# ECC_AGGR0_ECC_AGGR register map
Vendor: Texas Instruments
Registers are 32-bit, access not given, reset 0x0 unless marked. A register's access mark holds for its fields unless they carry their own. Offsets are as the file gives them; [hi:lo] are bit positions.

## ECC_AGGR0_ECC_AGGR (part 2 of 4)
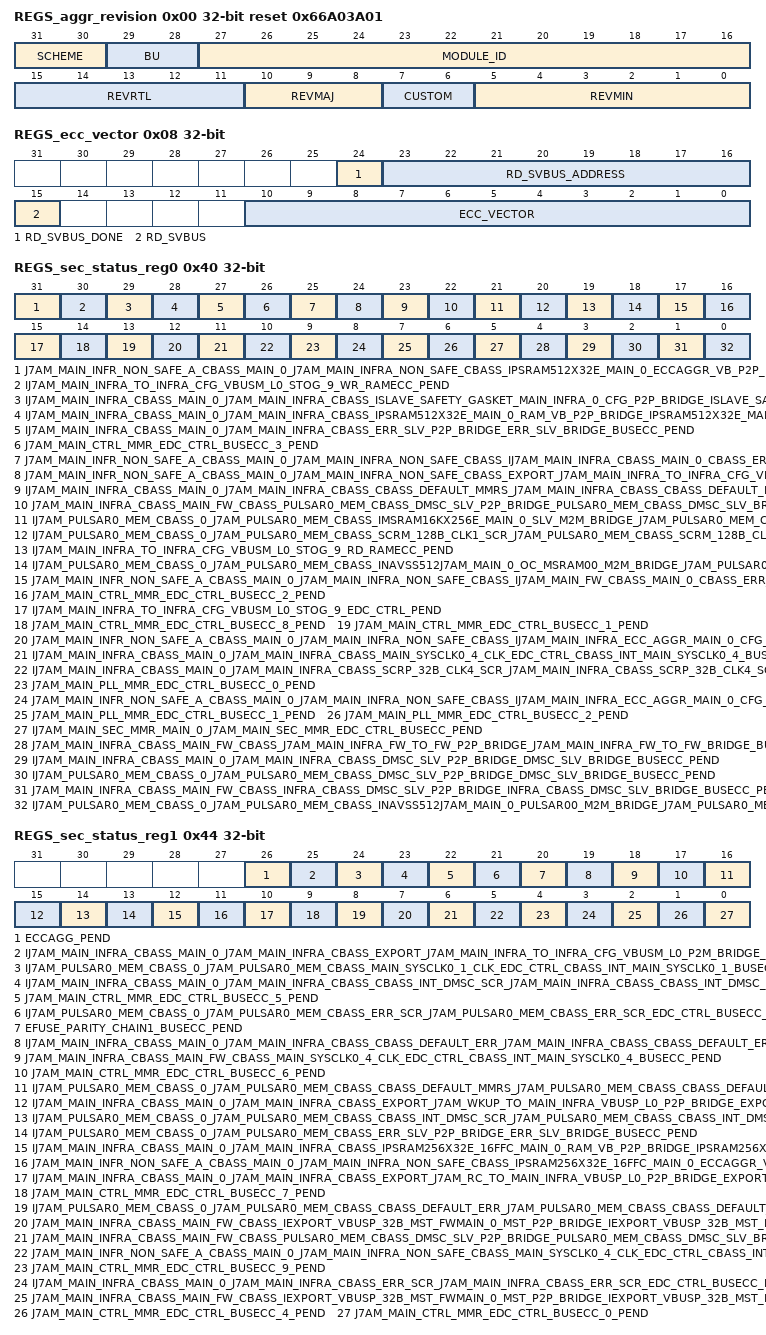
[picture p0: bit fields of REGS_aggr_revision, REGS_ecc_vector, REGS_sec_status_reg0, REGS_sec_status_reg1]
0x00 REGS_aggr_revision ro reset 0x66A03A01 — Revision parameters
  [31:30] SCHEME
  [29:28] BU
  [27:16] MODULE_ID
  [15:11] REVRTL — RTL version
  [10:8] REVMAJ — Major version
  [7:6] CUSTOM — Custom version
  [5:0] REVMIN — Minor version
0x08 REGS_ecc_vector — ECC Vector Register
  [24] RD_SVBUS_DONE — Status to indicate if read on serial VBUS is complete, write of any value will clear this bit. (access R/W1TC)
  [23:16] RD_SVBUS_ADDRESS rw — Read address
  [15] RD_SVBUS — Write 1 to trigger a read on the serial VBUS (access R/W1TS)
  [10:0] ECC_VECTOR rw — Value written to select the corresponding ECC RAM for control or status
0x0C REGS_misc_status ro reset 0x3B — Misc Status
  [10:0] NUM_RAMS — Indicates the number of RAMS serviced by the ECC aggregator
0x10 REGS_reserved_svbus rw — Reference other documents that contain the ECC RAM wrapper and EDC controller serial vbus register sets.
  [31:0] DATA — Serial VBUS register data
0x3C REGS_sec_eoi_reg — EOI Register
  [0] EOI_WR — EOI Register (access R/W1TS)
0x40 REGS_sec_status_reg0 — Interrupt Status Register 0
  [31] J7AM_MAIN_INFR_NON_SAFE_A_CBASS_MAIN_0_J7AM_MAIN_INFRA_NON_SAFE_CBASS_IPSRAM512X32E_MAIN_0_ECCAGGR_VB_P2P_BRIDGE_IPSRAM512X32E_MAIN_0_ECCAGGR_VB_BRIDGE_BUSECC_PEND — Interrupt Pending Status for j7am_main_infr_non_safe_a_cbass_main_0_j7am_main_infra_non_safe_cbass_Ipsram512x32e_main_0_eccaggr_vb_p2p_bridge_Ipsram512x32e_main_0_eccaggr_vb_bridge_busecc_pend (access R/W1TS)
  [30] IJ7AM_MAIN_INFRA_TO_INFRA_CFG_VBUSM_L0_STOG_9_WR_RAMECC_PEND — Interrupt Pending Status for Ij7am_main_infra_to_infra_cfg_vbusm_l0_stog_9_wr_ramecc_pend (access R/W1TS)
  [29] IJ7AM_MAIN_INFRA_CBASS_MAIN_0_J7AM_MAIN_INFRA_CBASS_ISLAVE_SAFETY_GASKET_MAIN_INFRA_0_CFG_P2P_BRIDGE_ISLAVE_SAFETY_GASKET_MAIN_INFRA_0_CFG_BRIDGE_BUSECC_PEND — Interrupt Pending Status for Ij7am_main_infra_cbass_main_0_j7am_main_infra_cbass_Islave_safety_gasket_main_infra_0_cfg_p2p_bridge_Islave_safety_gasket_main_infra_0_cfg_bridge_busecc_pend (access R/W1TS)
  [28] IJ7AM_MAIN_INFRA_CBASS_MAIN_0_J7AM_MAIN_INFRA_CBASS_IPSRAM512X32E_MAIN_0_RAM_VB_P2P_BRIDGE_IPSRAM512X32E_MAIN_0_RAM_VB_BRIDGE_BUSECC_PEND — Interrupt Pending Status for Ij7am_main_infra_cbass_main_0_j7am_main_infra_cbass_Ipsram512x32e_main_0_ram_vb_p2p_bridge_Ipsram512x32e_main_0_ram_vb_bridge_busecc_pend (access R/W1TS)
  [27] IJ7AM_MAIN_INFRA_CBASS_MAIN_0_J7AM_MAIN_INFRA_CBASS_ERR_SLV_P2P_BRIDGE_ERR_SLV_BRIDGE_BUSECC_PEND — Interrupt Pending Status for Ij7am_main_infra_cbass_main_0_j7am_main_infra_cbass_err_slv_p2p_bridge_err_slv_bridge_busecc_pend (access R/W1TS)
  [26] J7AM_MAIN_CTRL_MMR_EDC_CTRL_BUSECC_3_PEND — Interrupt Pending Status for j7am_main_ctrl_mmr_edc_ctrl_busecc_3_pend (access R/W1TS)
  [25] J7AM_MAIN_INFR_NON_SAFE_A_CBASS_MAIN_0_J7AM_MAIN_INFRA_NON_SAFE_CBASS_IJ7AM_MAIN_INFRA_CBASS_MAIN_0_CBASS_ERR_SLV_P2P_BRIDGE_IJ7AM_MAIN_INFRA_CBASS_MAIN_0_CBASS_ERR_SLV_BRIDGE_BUSECC_PEND — Interrupt Pending Status for j7am_main_infr_non_safe_a_cbass_main_0_j7am_main_infra_non_safe_cbass_Ij7am_main_infra_cbass_main_0_cbass_err_slv_p2p_bridge_Ij7am_main_infra_cbass_main_0_cbass_err_slv_bridge_busecc_pend (access R/W1TS)
  [24] J7AM_MAIN_INFR_NON_SAFE_A_CBASS_MAIN_0_J7AM_MAIN_INFRA_NON_SAFE_CBASS_EXPORT_J7AM_MAIN_INFRA_TO_INFRA_CFG_VBUSM_L0_M2P_BRIDGE_EXPORT_J7AM_MAIN_INFRA_TO_INFRA_CFG_VBUSM_L0_BRIDGE_BUSECC_PEND — Interrupt Pending Status for j7am_main_infr_non_safe_a_cbass_main_0_j7am_main_infra_non_safe_cbass_export_j7am_main_infra_to_infra_cfg_vbusm_l0_m2p_bridge_export_j7am_main_infra_to_infra_cfg_vbusm_l0_bridge_busecc_pend (access R/W1TS)
  [23] IJ7AM_MAIN_INFRA_CBASS_MAIN_0_J7AM_MAIN_INFRA_CBASS_CBASS_DEFAULT_MMRS_J7AM_MAIN_INFRA_CBASS_CBASS_DEFAULT_MMRS_EDC_CTRL_BUSECC_PEND — Interrupt Pending Status for Ij7am_main_infra_cbass_main_0_j7am_main_infra_cbass_cbass_default_mmrs_j7am_main_infra_cbass_cbass_default_mmrs_edc_ctrl_busecc_pend (access R/W1TS)
  [22] J7AM_MAIN_INFRA_CBASS_MAIN_FW_CBASS_PULSAR0_MEM_CBASS_DMSC_SLV_P2P_BRIDGE_PULSAR0_MEM_CBASS_DMSC_SLV_BRIDGE_DST_BUSECC_PEND — Interrupt Pending Status for j7am_main_infra_cbass_main_fw_cbass_pulsar0_mem_cbass_dmsc_slv_p2p_bridge_pulsar0_mem_cbass_dmsc_slv_bridge_dst_busecc_pend (access R/W1TS)
  [21] IJ7AM_PULSAR0_MEM_CBASS_0_J7AM_PULSAR0_MEM_CBASS_IMSRAM16KX256E_MAIN_0_SLV_M2M_BRIDGE_J7AM_PULSAR0_MEM_CBASS_IMSRAM16KX256E_MAIN_0_SLV_M2M_BRIDGE_SRC_EDC_CTRL_BUSECC_PEND — Interrupt Pending Status for Ij7am_pulsar0_mem_cbass_0_j7am_pulsar0_mem_cbass_Imsram16kx256e_main_0_slv_m2m_bridge_j7am_pulsar0_mem_cbass_Imsram16kx256e_main_0_slv_m2m_bridge_src_edc_ctrl_busecc_pend (access R/W1TS)
  [20] IJ7AM_PULSAR0_MEM_CBASS_0_J7AM_PULSAR0_MEM_CBASS_SCRM_128B_CLK1_SCR_J7AM_PULSAR0_MEM_CBASS_SCRM_128B_CLK1_SCR_EDC_CTRL_BUSECC_PEND — Interrupt Pending Status for Ij7am_pulsar0_mem_cbass_0_j7am_pulsar0_mem_cbass_scrm_128b_clk1_scr_j7am_pulsar0_mem_cbass_scrm_128b_clk1_scr_edc_ctrl_busecc_pend (access R/W1TS)
  [19] IJ7AM_MAIN_INFRA_TO_INFRA_CFG_VBUSM_L0_STOG_9_RD_RAMECC_PEND — Interrupt Pending Status for Ij7am_main_infra_to_infra_cfg_vbusm_l0_stog_9_rd_ramecc_pend (access R/W1TS)
  [18] IJ7AM_PULSAR0_MEM_CBASS_0_J7AM_PULSAR0_MEM_CBASS_INAVSS512J7AM_MAIN_0_OC_MSRAM00_M2M_BRIDGE_J7AM_PULSAR0_MEM_CBASS_INAVSS512J7AM_MAIN_0_OC_MSRAM00_M2M_BRIDGE_SRC_EDC_CTRL_BUSECC_PEND — Interrupt Pending Status for Ij7am_pulsar0_mem_cbass_0_j7am_pulsar0_mem_cbass_Inavss512j7am_main_0_oc_msram00_m2m_bridge_j7am_pulsar0_mem_cbass_Inavss512j7am_main_0_oc_msram00_m2m_bridge_src_edc_ctrl_busecc_pend (access R/W1TS)
  [17] J7AM_MAIN_INFR_NON_SAFE_A_CBASS_MAIN_0_J7AM_MAIN_INFRA_NON_SAFE_CBASS_IJ7AM_MAIN_FW_CBASS_MAIN_0_CBASS_ERR_SLV_P2P_BRIDGE_IJ7AM_MAIN_FW_CBASS_MAIN_0_CBASS_ERR_SLV_BRIDGE_BUSECC_PEND — Interrupt Pending Status for j7am_main_infr_non_safe_a_cbass_main_0_j7am_main_infra_non_safe_cbass_Ij7am_main_fw_cbass_main_0_cbass_err_slv_p2p_bridge_Ij7am_main_fw_cbass_main_0_cbass_err_slv_bridge_busecc_pend (access R/W1TS)
  [16] J7AM_MAIN_CTRL_MMR_EDC_CTRL_BUSECC_2_PEND — Interrupt Pending Status for j7am_main_ctrl_mmr_edc_ctrl_busecc_2_pend (access R/W1TS)
  [15] IJ7AM_MAIN_INFRA_TO_INFRA_CFG_VBUSM_L0_STOG_9_EDC_CTRL_PEND — Interrupt Pending Status for Ij7am_main_infra_to_infra_cfg_vbusm_l0_stog_9_edc_ctrl_pend (access R/W1TS)
  [14] J7AM_MAIN_CTRL_MMR_EDC_CTRL_BUSECC_8_PEND — Interrupt Pending Status for j7am_main_ctrl_mmr_edc_ctrl_busecc_8_pend (access R/W1TS)
  [13] J7AM_MAIN_CTRL_MMR_EDC_CTRL_BUSECC_1_PEND — Interrupt Pending Status for j7am_main_ctrl_mmr_edc_ctrl_busecc_1_pend (access R/W1TS)
  [12] J7AM_MAIN_INFR_NON_SAFE_A_CBASS_MAIN_0_J7AM_MAIN_INFRA_NON_SAFE_CBASS_IJ7AM_MAIN_INFRA_ECC_AGGR_MAIN_0_CFG_P2P_BRIDGE_IJ7AM_MAIN_INFRA_ECC_AGGR_MAIN_0_CFG_BRIDGE_SRC_BUSECC_PEND — Interrupt Pending Status for j7am_main_infr_non_safe_a_cbass_main_0_j7am_main_infra_non_safe_cbass_Ij7am_main_infra_ecc_aggr_main_0_cfg_p2p_bridge_Ij7am_main_infra_ecc_aggr_main_0_cfg_bridge_src_busecc_pend (access R/W1TS)
  [11] IJ7AM_MAIN_INFRA_CBASS_MAIN_0_J7AM_MAIN_INFRA_CBASS_MAIN_SYSCLK0_4_CLK_EDC_CTRL_CBASS_INT_MAIN_SYSCLK0_4_BUSECC_PEND — Interrupt Pending Status for Ij7am_main_infra_cbass_main_0_j7am_main_infra_cbass_main_SYSCLK0_4_clk_edc_ctrl_cbass_int_main_SYSCLK0_4_busecc_pend (access R/W1TS)
  [10] IJ7AM_MAIN_INFRA_CBASS_MAIN_0_J7AM_MAIN_INFRA_CBASS_SCRP_32B_CLK4_SCR_J7AM_MAIN_INFRA_CBASS_SCRP_32B_CLK4_SCR_EDC_CTRL_BUSECC_PEND — Interrupt Pending Status for Ij7am_main_infra_cbass_main_0_j7am_main_infra_cbass_scrp_32b_clk4_scr_j7am_main_infra_cbass_scrp_32b_clk4_scr_edc_ctrl_busecc_pend (access R/W1TS)
  [9] J7AM_MAIN_PLL_MMR_EDC_CTRL_BUSECC_0_PEND — Interrupt Pending Status for j7am_main_pll_mmr_edc_ctrl_busecc_0_pend (access R/W1TS)
  [8] J7AM_MAIN_INFR_NON_SAFE_A_CBASS_MAIN_0_J7AM_MAIN_INFRA_NON_SAFE_CBASS_IJ7AM_MAIN_INFRA_ECC_AGGR_MAIN_0_CFG_P2P_BRIDGE_IJ7AM_MAIN_INFRA_ECC_AGGR_MAIN_0_CFG_BRIDGE_DST_BUSECC_PEND — Interrupt Pending Status for j7am_main_infr_non_safe_a_cbass_main_0_j7am_main_infra_non_safe_cbass_Ij7am_main_infra_ecc_aggr_main_0_cfg_p2p_bridge_Ij7am_main_infra_ecc_aggr_main_0_cfg_bridge_dst_busecc_pend (access R/W1TS)
  [7] J7AM_MAIN_PLL_MMR_EDC_CTRL_BUSECC_1_PEND — Interrupt Pending Status for j7am_main_pll_mmr_edc_ctrl_busecc_1_pend (access R/W1TS)
  [6] J7AM_MAIN_PLL_MMR_EDC_CTRL_BUSECC_2_PEND — Interrupt Pending Status for j7am_main_pll_mmr_edc_ctrl_busecc_2_pend (access R/W1TS)
  [5] IJ7AM_MAIN_SEC_MMR_MAIN_0_J7AM_MAIN_SEC_MMR_EDC_CTRL_BUSECC_PEND — Interrupt Pending Status for Ij7am_main_sec_mmr_main_0_j7am_main_sec_mmr_edc_ctrl_busecc_pend (access R/W1TS)
  [4] J7AM_MAIN_INFRA_CBASS_MAIN_FW_CBASS_J7AM_MAIN_INFRA_FW_TO_FW_P2P_BRIDGE_J7AM_MAIN_INFRA_FW_TO_FW_BRIDGE_BUSECC_PEND — Interrupt Pending Status for j7am_main_infra_cbass_main_fw_cbass_j7am_main_infra_fw_to_fw_p2p_bridge_j7am_main_infra_fw_to_fw_bridge_busecc_pend (access R/W1TS)
  [3] IJ7AM_MAIN_INFRA_CBASS_MAIN_0_J7AM_MAIN_INFRA_CBASS_DMSC_SLV_P2P_BRIDGE_DMSC_SLV_BRIDGE_BUSECC_PEND — Interrupt Pending Status for Ij7am_main_infra_cbass_main_0_j7am_main_infra_cbass_dmsc_slv_p2p_bridge_dmsc_slv_bridge_busecc_pend (access R/W1TS)
  [2] IJ7AM_PULSAR0_MEM_CBASS_0_J7AM_PULSAR0_MEM_CBASS_DMSC_SLV_P2P_BRIDGE_DMSC_SLV_BRIDGE_BUSECC_PEND — Interrupt Pending Status for Ij7am_pulsar0_mem_cbass_0_j7am_pulsar0_mem_cbass_dmsc_slv_p2p_bridge_dmsc_slv_bridge_busecc_pend (access R/W1TS)
  [1] J7AM_MAIN_INFRA_CBASS_MAIN_FW_CBASS_INFRA_CBASS_DMSC_SLV_P2P_BRIDGE_INFRA_CBASS_DMSC_SLV_BRIDGE_BUSECC_PEND — Interrupt Pending Status for j7am_main_infra_cbass_main_fw_cbass_infra_cbass_dmsc_slv_p2p_bridge_infra_cbass_dmsc_slv_bridge_busecc_pend (access R/W1TS)
  [0] IJ7AM_PULSAR0_MEM_CBASS_0_J7AM_PULSAR0_MEM_CBASS_INAVSS512J7AM_MAIN_0_PULSAR00_M2M_BRIDGE_J7AM_PULSAR0_MEM_CBASS_INAVSS512J7AM_MAIN_0_PULSAR00_M2M_BRIDGE_SRC_EDC_CTRL_BUSECC_PEND — Interrupt Pending Status for Ij7am_pulsar0_mem_cbass_0_j7am_pulsar0_mem_cbass_Inavss512j7am_main_0_pulsar00_m2m_bridge_j7am_pulsar0_mem_cbass_Inavss512j7am_main_0_pulsar00_m2m_bridge_src_edc_ctrl_busecc_pend (access R/W1TS)
0x44 REGS_sec_status_reg1 — Interrupt Status Register 1
  [26] ECCAGG_PEND — Interrupt Pending Status for eccagg_pend (access R/W1TS)
  [25] IJ7AM_MAIN_INFRA_CBASS_MAIN_0_J7AM_MAIN_INFRA_CBASS_EXPORT_J7AM_MAIN_INFRA_TO_INFRA_CFG_VBUSM_L0_P2M_BRIDGE_EXPORT_J7AM_MAIN_INFRA_TO_INFRA_CFG_VBUSM_L0_BRIDGE_BUSECC_PEND — Interrupt Pending Status for Ij7am_main_infra_cbass_main_0_j7am_main_infra_cbass_export_j7am_main_infra_to_infra_cfg_vbusm_l0_p2m_bridge_export_j7am_main_infra_to_infra_cfg_vbusm_l0_bridge_busecc_pend (access R/W1TS)
  [24] IJ7AM_PULSAR0_MEM_CBASS_0_J7AM_PULSAR0_MEM_CBASS_MAIN_SYSCLK0_1_CLK_EDC_CTRL_CBASS_INT_MAIN_SYSCLK0_1_BUSECC_PEND — Interrupt Pending Status for Ij7am_pulsar0_mem_cbass_0_j7am_pulsar0_mem_cbass_main_SYSCLK0_1_clk_edc_ctrl_cbass_int_main_SYSCLK0_1_busecc_pend (access R/W1TS)
  [23] IJ7AM_MAIN_INFRA_CBASS_MAIN_0_J7AM_MAIN_INFRA_CBASS_CBASS_INT_DMSC_SCR_J7AM_MAIN_INFRA_CBASS_CBASS_INT_DMSC_SCR_EDC_CTRL_BUSECC_PEND — Interrupt Pending Status for Ij7am_main_infra_cbass_main_0_j7am_main_infra_cbass_cbass_int_dmsc_scr_j7am_main_infra_cbass_cbass_int_dmsc_scr_edc_ctrl_busecc_pend (access R/W1TS)
  [22] J7AM_MAIN_CTRL_MMR_EDC_CTRL_BUSECC_5_PEND — Interrupt Pending Status for j7am_main_ctrl_mmr_edc_ctrl_busecc_5_pend (access R/W1TS)
  [21] IJ7AM_PULSAR0_MEM_CBASS_0_J7AM_PULSAR0_MEM_CBASS_ERR_SCR_J7AM_PULSAR0_MEM_CBASS_ERR_SCR_EDC_CTRL_BUSECC_PEND — Interrupt Pending Status for Ij7am_pulsar0_mem_cbass_0_j7am_pulsar0_mem_cbass_err_scr_j7am_pulsar0_mem_cbass_err_scr_edc_ctrl_busecc_pend (access R/W1TS)
  [20] EFUSE_PARITY_CHAIN1_BUSECC_PEND — Interrupt Pending Status for efuse_parity_chain1_busecc_pend (access R/W1TS)
  [19] IJ7AM_MAIN_INFRA_CBASS_MAIN_0_J7AM_MAIN_INFRA_CBASS_CBASS_DEFAULT_ERR_J7AM_MAIN_INFRA_CBASS_CBASS_DEFAULT_ERR_EDC_CTRL_BUSECC_PEND — Interrupt Pending Status for Ij7am_main_infra_cbass_main_0_j7am_main_infra_cbass_cbass_default_err_j7am_main_infra_cbass_cbass_default_err_edc_ctrl_busecc_pend (access R/W1TS)
  [18] J7AM_MAIN_INFRA_CBASS_MAIN_FW_CBASS_MAIN_SYSCLK0_4_CLK_EDC_CTRL_CBASS_INT_MAIN_SYSCLK0_4_BUSECC_PEND — Interrupt Pending Status for j7am_main_infra_cbass_main_fw_cbass_main_SYSCLK0_4_clk_edc_ctrl_cbass_int_main_SYSCLK0_4_busecc_pend (access R/W1TS)
  [17] J7AM_MAIN_CTRL_MMR_EDC_CTRL_BUSECC_6_PEND — Interrupt Pending Status for j7am_main_ctrl_mmr_edc_ctrl_busecc_6_pend (access R/W1TS)
  [16] IJ7AM_PULSAR0_MEM_CBASS_0_J7AM_PULSAR0_MEM_CBASS_CBASS_DEFAULT_MMRS_J7AM_PULSAR0_MEM_CBASS_CBASS_DEFAULT_MMRS_EDC_CTRL_BUSECC_PEND — Interrupt Pending Status for Ij7am_pulsar0_mem_cbass_0_j7am_pulsar0_mem_cbass_cbass_default_mmrs_j7am_pulsar0_mem_cbass_cbass_default_mmrs_edc_ctrl_busecc_pend (access R/W1TS)
  [15] IJ7AM_MAIN_INFRA_CBASS_MAIN_0_J7AM_MAIN_INFRA_CBASS_EXPORT_J7AM_WKUP_TO_MAIN_INFRA_VBUSP_L0_P2P_BRIDGE_EXPORT_J7AM_WKUP_TO_MAIN_INFRA_VBUSP_L0_BRIDGE_BUSECC_PEND — Interrupt Pending Status for Ij7am_main_infra_cbass_main_0_j7am_main_infra_cbass_export_j7am_wkup_to_main_infra_vbusp_l0_p2p_bridge_export_j7am_wkup_to_main_infra_vbusp_l0_bridge_busecc_pend (access R/W1TS)
  [14] IJ7AM_PULSAR0_MEM_CBASS_0_J7AM_PULSAR0_MEM_CBASS_CBASS_INT_DMSC_SCR_J7AM_PULSAR0_MEM_CBASS_CBASS_INT_DMSC_SCR_EDC_CTRL_BUSECC_PEND — Interrupt Pending Status for Ij7am_pulsar0_mem_cbass_0_j7am_pulsar0_mem_cbass_cbass_int_dmsc_scr_j7am_pulsar0_mem_cbass_cbass_int_dmsc_scr_edc_ctrl_busecc_pend (access R/W1TS)
  [13] IJ7AM_PULSAR0_MEM_CBASS_0_J7AM_PULSAR0_MEM_CBASS_ERR_SLV_P2P_BRIDGE_ERR_SLV_BRIDGE_BUSECC_PEND — Interrupt Pending Status for Ij7am_pulsar0_mem_cbass_0_j7am_pulsar0_mem_cbass_err_slv_p2p_bridge_err_slv_bridge_busecc_pend (access R/W1TS)
  [12] IJ7AM_MAIN_INFRA_CBASS_MAIN_0_J7AM_MAIN_INFRA_CBASS_IPSRAM256X32E_16FFC_MAIN_0_RAM_VB_P2P_BRIDGE_IPSRAM256X32E_16FFC_MAIN_0_RAM_VB_BRIDGE_BUSECC_PEND — Interrupt Pending Status for Ij7am_main_infra_cbass_main_0_j7am_main_infra_cbass_Ipsram256x32e_16ffc_main_0_ram_vb_p2p_bridge_Ipsram256x32e_16ffc_main_0_ram_vb_bridge_busecc_pend (access R/W1TS)
  [11] J7AM_MAIN_INFR_NON_SAFE_A_CBASS_MAIN_0_J7AM_MAIN_INFRA_NON_SAFE_CBASS_IPSRAM256X32E_16FFC_MAIN_0_ECCAGGR_VB_P2P_BRIDGE_IPSRAM256X32E_16FFC_MAIN_0_ECCAGGR_VB_BRIDGE_BUSECC_PEND — Interrupt Pending Status for j7am_main_infr_non_safe_a_cbass_main_0_j7am_main_infra_non_safe_cbass_Ipsram256x32e_16ffc_main_0_eccaggr_vb_p2p_bridge_Ipsram256x32e_16ffc_main_0_eccaggr_vb_bridge_busecc_pend (access R/W1TS)
  [10] IJ7AM_MAIN_INFRA_CBASS_MAIN_0_J7AM_MAIN_INFRA_CBASS_EXPORT_J7AM_RC_TO_MAIN_INFRA_VBUSP_L0_P2P_BRIDGE_EXPORT_J7AM_RC_TO_MAIN_INFRA_VBUSP_L0_BRIDGE_BUSECC_PEND — Interrupt Pending Status for Ij7am_main_infra_cbass_main_0_j7am_main_infra_cbass_export_j7am_rc_to_main_infra_vbusp_l0_p2p_bridge_export_j7am_rc_to_main_infra_vbusp_l0_bridge_busecc_pend (access R/W1TS)
  [9] J7AM_MAIN_CTRL_MMR_EDC_CTRL_BUSECC_7_PEND — Interrupt Pending Status for j7am_main_ctrl_mmr_edc_ctrl_busecc_7_pend (access R/W1TS)
  [8] IJ7AM_PULSAR0_MEM_CBASS_0_J7AM_PULSAR0_MEM_CBASS_CBASS_DEFAULT_ERR_J7AM_PULSAR0_MEM_CBASS_CBASS_DEFAULT_ERR_EDC_CTRL_BUSECC_PEND — Interrupt Pending Status for Ij7am_pulsar0_mem_cbass_0_j7am_pulsar0_mem_cbass_cbass_default_err_j7am_pulsar0_mem_cbass_cbass_default_err_edc_ctrl_busecc_pend (access R/W1TS)
  [7] J7AM_MAIN_INFRA_CBASS_MAIN_FW_CBASS_IEXPORT_VBUSP_32B_MST_FWMAIN_0_MST_P2P_BRIDGE_IEXPORT_VBUSP_32B_MST_FWMAIN_0_MST_BRIDGE_SRC_BUSECC_PEND — Interrupt Pending Status for j7am_main_infra_cbass_main_fw_cbass_Iexport_vbusp_32b_mst_fwmain_0_mst_p2p_bridge_Iexport_vbusp_32b_mst_fwmain_0_mst_bridge_src_busecc_pend (access R/W1TS)
  [6] J7AM_MAIN_INFRA_CBASS_MAIN_FW_CBASS_PULSAR0_MEM_CBASS_DMSC_SLV_P2P_BRIDGE_PULSAR0_MEM_CBASS_DMSC_SLV_BRIDGE_SRC_BUSECC_PEND — Interrupt Pending Status for j7am_main_infra_cbass_main_fw_cbass_pulsar0_mem_cbass_dmsc_slv_p2p_bridge_pulsar0_mem_cbass_dmsc_slv_bridge_src_busecc_pend (access R/W1TS)
  [5] J7AM_MAIN_INFR_NON_SAFE_A_CBASS_MAIN_0_J7AM_MAIN_INFRA_NON_SAFE_CBASS_MAIN_SYSCLK0_4_CLK_EDC_CTRL_CBASS_INT_MAIN_SYSCLK0_4_BUSECC_PEND — Interrupt Pending Status for j7am_main_infr_non_safe_a_cbass_main_0_j7am_main_infra_non_safe_cbass_main_SYSCLK0_4_clk_edc_ctrl_cbass_int_main_SYSCLK0_4_busecc_pend (access R/W1TS)
  [4] J7AM_MAIN_CTRL_MMR_EDC_CTRL_BUSECC_9_PEND — Interrupt Pending Status for j7am_main_ctrl_mmr_edc_ctrl_busecc_9_pend (access R/W1TS)
  [3] IJ7AM_MAIN_INFRA_CBASS_MAIN_0_J7AM_MAIN_INFRA_CBASS_ERR_SCR_J7AM_MAIN_INFRA_CBASS_ERR_SCR_EDC_CTRL_BUSECC_PEND — Interrupt Pending Status for Ij7am_main_infra_cbass_main_0_j7am_main_infra_cbass_err_scr_j7am_main_infra_cbass_err_scr_edc_ctrl_busecc_pend (access R/W1TS)
  [2] J7AM_MAIN_INFRA_CBASS_MAIN_FW_CBASS_IEXPORT_VBUSP_32B_MST_FWMAIN_0_MST_P2P_BRIDGE_IEXPORT_VBUSP_32B_MST_FWMAIN_0_MST_BRIDGE_DST_BUSECC_PEND — Interrupt Pending Status for j7am_main_infra_cbass_main_fw_cbass_Iexport_vbusp_32b_mst_fwmain_0_mst_p2p_bridge_Iexport_vbusp_32b_mst_fwmain_0_mst_bridge_dst_busecc_pend (access R/W1TS)
  [1] J7AM_MAIN_CTRL_MMR_EDC_CTRL_BUSECC_4_PEND — Interrupt Pending Status for j7am_main_ctrl_mmr_edc_ctrl_busecc_4_pend (access R/W1TS)
  [0] J7AM_MAIN_CTRL_MMR_EDC_CTRL_BUSECC_0_PEND — Interrupt Pending Status for j7am_main_ctrl_mmr_edc_ctrl_busecc_0_pend (access R/W1TS)
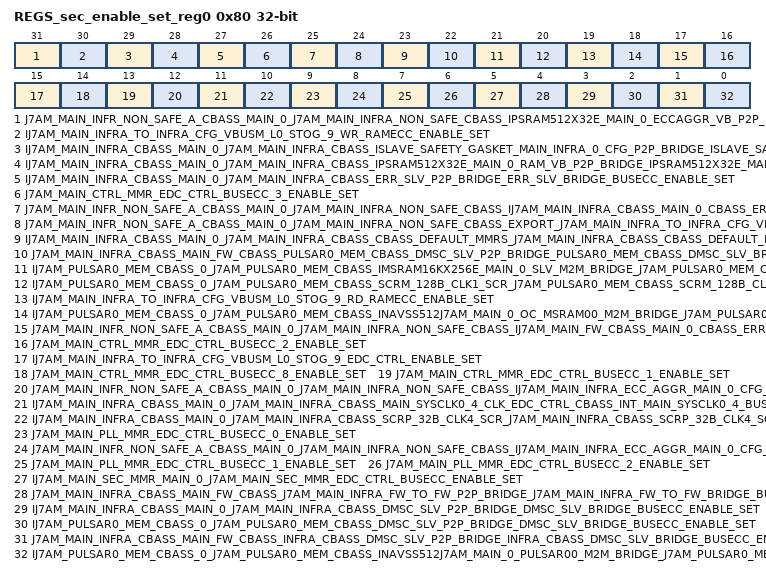
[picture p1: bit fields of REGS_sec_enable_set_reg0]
0x80 REGS_sec_enable_set_reg0 — Interrupt Enable Set Register 0
  [31] J7AM_MAIN_INFR_NON_SAFE_A_CBASS_MAIN_0_J7AM_MAIN_INFRA_NON_SAFE_CBASS_IPSRAM512X32E_MAIN_0_ECCAGGR_VB_P2P_BRIDGE_IPSRAM512X32E_MAIN_0_ECCAGGR_VB_BRIDGE_BUSECC_ENABLE_SET — Interrupt Enable Set Register for j7am_main_infr_non_safe_a_cbass_main_0_j7am_main_infra_non_safe_cbass_Ipsram512x32e_main_0_eccaggr_vb_p2p_bridge_Ipsram512x32e_main_0_eccaggr_vb_bridge_busecc_pend (access R/W1TS)
  [30] IJ7AM_MAIN_INFRA_TO_INFRA_CFG_VBUSM_L0_STOG_9_WR_RAMECC_ENABLE_SET — Interrupt Enable Set Register for Ij7am_main_infra_to_infra_cfg_vbusm_l0_stog_9_wr_ramecc_pend (access R/W1TS)
  [29] IJ7AM_MAIN_INFRA_CBASS_MAIN_0_J7AM_MAIN_INFRA_CBASS_ISLAVE_SAFETY_GASKET_MAIN_INFRA_0_CFG_P2P_BRIDGE_ISLAVE_SAFETY_GASKET_MAIN_INFRA_0_CFG_BRIDGE_BUSECC_ENABLE_SET — Interrupt Enable Set Register for Ij7am_main_infra_cbass_main_0_j7am_main_infra_cbass_Islave_safety_gasket_main_infra_0_cfg_p2p_bridge_Islave_safety_gasket_main_infra_0_cfg_bridge_busecc_pend (access R/W1TS)
  [28] IJ7AM_MAIN_INFRA_CBASS_MAIN_0_J7AM_MAIN_INFRA_CBASS_IPSRAM512X32E_MAIN_0_RAM_VB_P2P_BRIDGE_IPSRAM512X32E_MAIN_0_RAM_VB_BRIDGE_BUSECC_ENABLE_SET — Interrupt Enable Set Register for Ij7am_main_infra_cbass_main_0_j7am_main_infra_cbass_Ipsram512x32e_main_0_ram_vb_p2p_bridge_Ipsram512x32e_main_0_ram_vb_bridge_busecc_pend (access R/W1TS)
  [27] IJ7AM_MAIN_INFRA_CBASS_MAIN_0_J7AM_MAIN_INFRA_CBASS_ERR_SLV_P2P_BRIDGE_ERR_SLV_BRIDGE_BUSECC_ENABLE_SET — Interrupt Enable Set Register for Ij7am_main_infra_cbass_main_0_j7am_main_infra_cbass_err_slv_p2p_bridge_err_slv_bridge_busecc_pend (access R/W1TS)
  [26] J7AM_MAIN_CTRL_MMR_EDC_CTRL_BUSECC_3_ENABLE_SET — Interrupt Enable Set Register for j7am_main_ctrl_mmr_edc_ctrl_busecc_3_pend (access R/W1TS)
  [25] J7AM_MAIN_INFR_NON_SAFE_A_CBASS_MAIN_0_J7AM_MAIN_INFRA_NON_SAFE_CBASS_IJ7AM_MAIN_INFRA_CBASS_MAIN_0_CBASS_ERR_SLV_P2P_BRIDGE_IJ7AM_MAIN_INFRA_CBASS_MAIN_0_CBASS_ERR_SLV_BRIDGE_BUSECC_ENABLE_SET — Interrupt Enable Set Register for j7am_main_infr_non_safe_a_cbass_main_0_j7am_main_infra_non_safe_cbass_Ij7am_main_infra_cbass_main_0_cbass_err_slv_p2p_bridge_Ij7am_main_infra_cbass_main_0_cbass_err_slv_bridge_busecc_pend (access R/W1TS)
  [24] J7AM_MAIN_INFR_NON_SAFE_A_CBASS_MAIN_0_J7AM_MAIN_INFRA_NON_SAFE_CBASS_EXPORT_J7AM_MAIN_INFRA_TO_INFRA_CFG_VBUSM_L0_M2P_BRIDGE_EXPORT_J7AM_MAIN_INFRA_TO_INFRA_CFG_VBUSM_L0_BRIDGE_BUSECC_ENABLE_SET — Interrupt Enable Set Register for j7am_main_infr_non_safe_a_cbass_main_0_j7am_main_infra_non_safe_cbass_export_j7am_main_infra_to_infra_cfg_vbusm_l0_m2p_bridge_export_j7am_main_infra_to_infra_cfg_vbusm_l0_bridge_busecc_pend (access R/W1TS)
  [23] IJ7AM_MAIN_INFRA_CBASS_MAIN_0_J7AM_MAIN_INFRA_CBASS_CBASS_DEFAULT_MMRS_J7AM_MAIN_INFRA_CBASS_CBASS_DEFAULT_MMRS_EDC_CTRL_BUSECC_ENABLE_SET — Interrupt Enable Set Register for Ij7am_main_infra_cbass_main_0_j7am_main_infra_cbass_cbass_default_mmrs_j7am_main_infra_cbass_cbass_default_mmrs_edc_ctrl_busecc_pend (access R/W1TS)
  [22] J7AM_MAIN_INFRA_CBASS_MAIN_FW_CBASS_PULSAR0_MEM_CBASS_DMSC_SLV_P2P_BRIDGE_PULSAR0_MEM_CBASS_DMSC_SLV_BRIDGE_DST_BUSECC_ENABLE_SET — Interrupt Enable Set Register for j7am_main_infra_cbass_main_fw_cbass_pulsar0_mem_cbass_dmsc_slv_p2p_bridge_pulsar0_mem_cbass_dmsc_slv_bridge_dst_busecc_pend (access R/W1TS)
  [21] IJ7AM_PULSAR0_MEM_CBASS_0_J7AM_PULSAR0_MEM_CBASS_IMSRAM16KX256E_MAIN_0_SLV_M2M_BRIDGE_J7AM_PULSAR0_MEM_CBASS_IMSRAM16KX256E_MAIN_0_SLV_M2M_BRIDGE_SRC_EDC_CTRL_BUSECC_ENABLE_SET — Interrupt Enable Set Register for Ij7am_pulsar0_mem_cbass_0_j7am_pulsar0_mem_cbass_Imsram16kx256e_main_0_slv_m2m_bridge_j7am_pulsar0_mem_cbass_Imsram16kx256e_main_0_slv_m2m_bridge_src_edc_ctrl_busecc_pend (access R/W1TS)
  [20] IJ7AM_PULSAR0_MEM_CBASS_0_J7AM_PULSAR0_MEM_CBASS_SCRM_128B_CLK1_SCR_J7AM_PULSAR0_MEM_CBASS_SCRM_128B_CLK1_SCR_EDC_CTRL_BUSECC_ENABLE_SET — Interrupt Enable Set Register for Ij7am_pulsar0_mem_cbass_0_j7am_pulsar0_mem_cbass_scrm_128b_clk1_scr_j7am_pulsar0_mem_cbass_scrm_128b_clk1_scr_edc_ctrl_busecc_pend (access R/W1TS)
  [19] IJ7AM_MAIN_INFRA_TO_INFRA_CFG_VBUSM_L0_STOG_9_RD_RAMECC_ENABLE_SET — Interrupt Enable Set Register for Ij7am_main_infra_to_infra_cfg_vbusm_l0_stog_9_rd_ramecc_pend (access R/W1TS)
  [18] IJ7AM_PULSAR0_MEM_CBASS_0_J7AM_PULSAR0_MEM_CBASS_INAVSS512J7AM_MAIN_0_OC_MSRAM00_M2M_BRIDGE_J7AM_PULSAR0_MEM_CBASS_INAVSS512J7AM_MAIN_0_OC_MSRAM00_M2M_BRIDGE_SRC_EDC_CTRL_BUSECC_ENABLE_SET — Interrupt Enable Set Register for Ij7am_pulsar0_mem_cbass_0_j7am_pulsar0_mem_cbass_Inavss512j7am_main_0_oc_msram00_m2m_bridge_j7am_pulsar0_mem_cbass_Inavss512j7am_main_0_oc_msram00_m2m_bridge_src_edc_ctrl_busecc_pend (access R/W1TS)
  [17] J7AM_MAIN_INFR_NON_SAFE_A_CBASS_MAIN_0_J7AM_MAIN_INFRA_NON_SAFE_CBASS_IJ7AM_MAIN_FW_CBASS_MAIN_0_CBASS_ERR_SLV_P2P_BRIDGE_IJ7AM_MAIN_FW_CBASS_MAIN_0_CBASS_ERR_SLV_BRIDGE_BUSECC_ENABLE_SET — Interrupt Enable Set Register for j7am_main_infr_non_safe_a_cbass_main_0_j7am_main_infra_non_safe_cbass_Ij7am_main_fw_cbass_main_0_cbass_err_slv_p2p_bridge_Ij7am_main_fw_cbass_main_0_cbass_err_slv_bridge_busecc_pend (access R/W1TS)
  [16] J7AM_MAIN_CTRL_MMR_EDC_CTRL_BUSECC_2_ENABLE_SET — Interrupt Enable Set Register for j7am_main_ctrl_mmr_edc_ctrl_busecc_2_pend (access R/W1TS)
  [15] IJ7AM_MAIN_INFRA_TO_INFRA_CFG_VBUSM_L0_STOG_9_EDC_CTRL_ENABLE_SET — Interrupt Enable Set Register for Ij7am_main_infra_to_infra_cfg_vbusm_l0_stog_9_edc_ctrl_pend (access R/W1TS)
  [14] J7AM_MAIN_CTRL_MMR_EDC_CTRL_BUSECC_8_ENABLE_SET — Interrupt Enable Set Register for j7am_main_ctrl_mmr_edc_ctrl_busecc_8_pend (access R/W1TS)
  [13] J7AM_MAIN_CTRL_MMR_EDC_CTRL_BUSECC_1_ENABLE_SET — Interrupt Enable Set Register for j7am_main_ctrl_mmr_edc_ctrl_busecc_1_pend (access R/W1TS)
  [12] J7AM_MAIN_INFR_NON_SAFE_A_CBASS_MAIN_0_J7AM_MAIN_INFRA_NON_SAFE_CBASS_IJ7AM_MAIN_INFRA_ECC_AGGR_MAIN_0_CFG_P2P_BRIDGE_IJ7AM_MAIN_INFRA_ECC_AGGR_MAIN_0_CFG_BRIDGE_SRC_BUSECC_ENABLE_SET — Interrupt Enable Set Register for j7am_main_infr_non_safe_a_cbass_main_0_j7am_main_infra_non_safe_cbass_Ij7am_main_infra_ecc_aggr_main_0_cfg_p2p_bridge_Ij7am_main_infra_ecc_aggr_main_0_cfg_bridge_src_busecc_pend (access R/W1TS)
  [11] IJ7AM_MAIN_INFRA_CBASS_MAIN_0_J7AM_MAIN_INFRA_CBASS_MAIN_SYSCLK0_4_CLK_EDC_CTRL_CBASS_INT_MAIN_SYSCLK0_4_BUSECC_ENABLE_SET — Interrupt Enable Set Register for Ij7am_main_infra_cbass_main_0_j7am_main_infra_cbass_main_SYSCLK0_4_clk_edc_ctrl_cbass_int_main_SYSCLK0_4_busecc_pend (access R/W1TS)
  [10] IJ7AM_MAIN_INFRA_CBASS_MAIN_0_J7AM_MAIN_INFRA_CBASS_SCRP_32B_CLK4_SCR_J7AM_MAIN_INFRA_CBASS_SCRP_32B_CLK4_SCR_EDC_CTRL_BUSECC_ENABLE_SET — Interrupt Enable Set Register for Ij7am_main_infra_cbass_main_0_j7am_main_infra_cbass_scrp_32b_clk4_scr_j7am_main_infra_cbass_scrp_32b_clk4_scr_edc_ctrl_busecc_pend (access R/W1TS)
  [9] J7AM_MAIN_PLL_MMR_EDC_CTRL_BUSECC_0_ENABLE_SET — Interrupt Enable Set Register for j7am_main_pll_mmr_edc_ctrl_busecc_0_pend (access R/W1TS)
  [8] J7AM_MAIN_INFR_NON_SAFE_A_CBASS_MAIN_0_J7AM_MAIN_INFRA_NON_SAFE_CBASS_IJ7AM_MAIN_INFRA_ECC_AGGR_MAIN_0_CFG_P2P_BRIDGE_IJ7AM_MAIN_INFRA_ECC_AGGR_MAIN_0_CFG_BRIDGE_DST_BUSECC_ENABLE_SET — Interrupt Enable Set Register for j7am_main_infr_non_safe_a_cbass_main_0_j7am_main_infra_non_safe_cbass_Ij7am_main_infra_ecc_aggr_main_0_cfg_p2p_bridge_Ij7am_main_infra_ecc_aggr_main_0_cfg_bridge_dst_busecc_pend (access R/W1TS)
  [7] J7AM_MAIN_PLL_MMR_EDC_CTRL_BUSECC_1_ENABLE_SET — Interrupt Enable Set Register for j7am_main_pll_mmr_edc_ctrl_busecc_1_pend (access R/W1TS)
  [6] J7AM_MAIN_PLL_MMR_EDC_CTRL_BUSECC_2_ENABLE_SET — Interrupt Enable Set Register for j7am_main_pll_mmr_edc_ctrl_busecc_2_pend (access R/W1TS)
  [5] IJ7AM_MAIN_SEC_MMR_MAIN_0_J7AM_MAIN_SEC_MMR_EDC_CTRL_BUSECC_ENABLE_SET — Interrupt Enable Set Register for Ij7am_main_sec_mmr_main_0_j7am_main_sec_mmr_edc_ctrl_busecc_pend (access R/W1TS)
  [4] J7AM_MAIN_INFRA_CBASS_MAIN_FW_CBASS_J7AM_MAIN_INFRA_FW_TO_FW_P2P_BRIDGE_J7AM_MAIN_INFRA_FW_TO_FW_BRIDGE_BUSECC_ENABLE_SET — Interrupt Enable Set Register for j7am_main_infra_cbass_main_fw_cbass_j7am_main_infra_fw_to_fw_p2p_bridge_j7am_main_infra_fw_to_fw_bridge_busecc_pend (access R/W1TS)
  [3] IJ7AM_MAIN_INFRA_CBASS_MAIN_0_J7AM_MAIN_INFRA_CBASS_DMSC_SLV_P2P_BRIDGE_DMSC_SLV_BRIDGE_BUSECC_ENABLE_SET — Interrupt Enable Set Register for Ij7am_main_infra_cbass_main_0_j7am_main_infra_cbass_dmsc_slv_p2p_bridge_dmsc_slv_bridge_busecc_pend (access R/W1TS)
  [2] IJ7AM_PULSAR0_MEM_CBASS_0_J7AM_PULSAR0_MEM_CBASS_DMSC_SLV_P2P_BRIDGE_DMSC_SLV_BRIDGE_BUSECC_ENABLE_SET — Interrupt Enable Set Register for Ij7am_pulsar0_mem_cbass_0_j7am_pulsar0_mem_cbass_dmsc_slv_p2p_bridge_dmsc_slv_bridge_busecc_pend (access R/W1TS)
  [1] J7AM_MAIN_INFRA_CBASS_MAIN_FW_CBASS_INFRA_CBASS_DMSC_SLV_P2P_BRIDGE_INFRA_CBASS_DMSC_SLV_BRIDGE_BUSECC_ENABLE_SET — Interrupt Enable Set Register for j7am_main_infra_cbass_main_fw_cbass_infra_cbass_dmsc_slv_p2p_bridge_infra_cbass_dmsc_slv_bridge_busecc_pend (access R/W1TS)
  [0] IJ7AM_PULSAR0_MEM_CBASS_0_J7AM_PULSAR0_MEM_CBASS_INAVSS512J7AM_MAIN_0_PULSAR00_M2M_BRIDGE_J7AM_PULSAR0_MEM_CBASS_INAVSS512J7AM_MAIN_0_PULSAR00_M2M_BRIDGE_SRC_EDC_CTRL_BUSECC_ENABLE_SET — Interrupt Enable Set Register for Ij7am_pulsar0_mem_cbass_0_j7am_pulsar0_mem_cbass_Inavss512j7am_main_0_pulsar00_m2m_bridge_j7am_pulsar0_mem_cbass_Inavss512j7am_main_0_pulsar00_m2m_bridge_src_edc_ctrl_busecc_pend (access R/W1TS)
